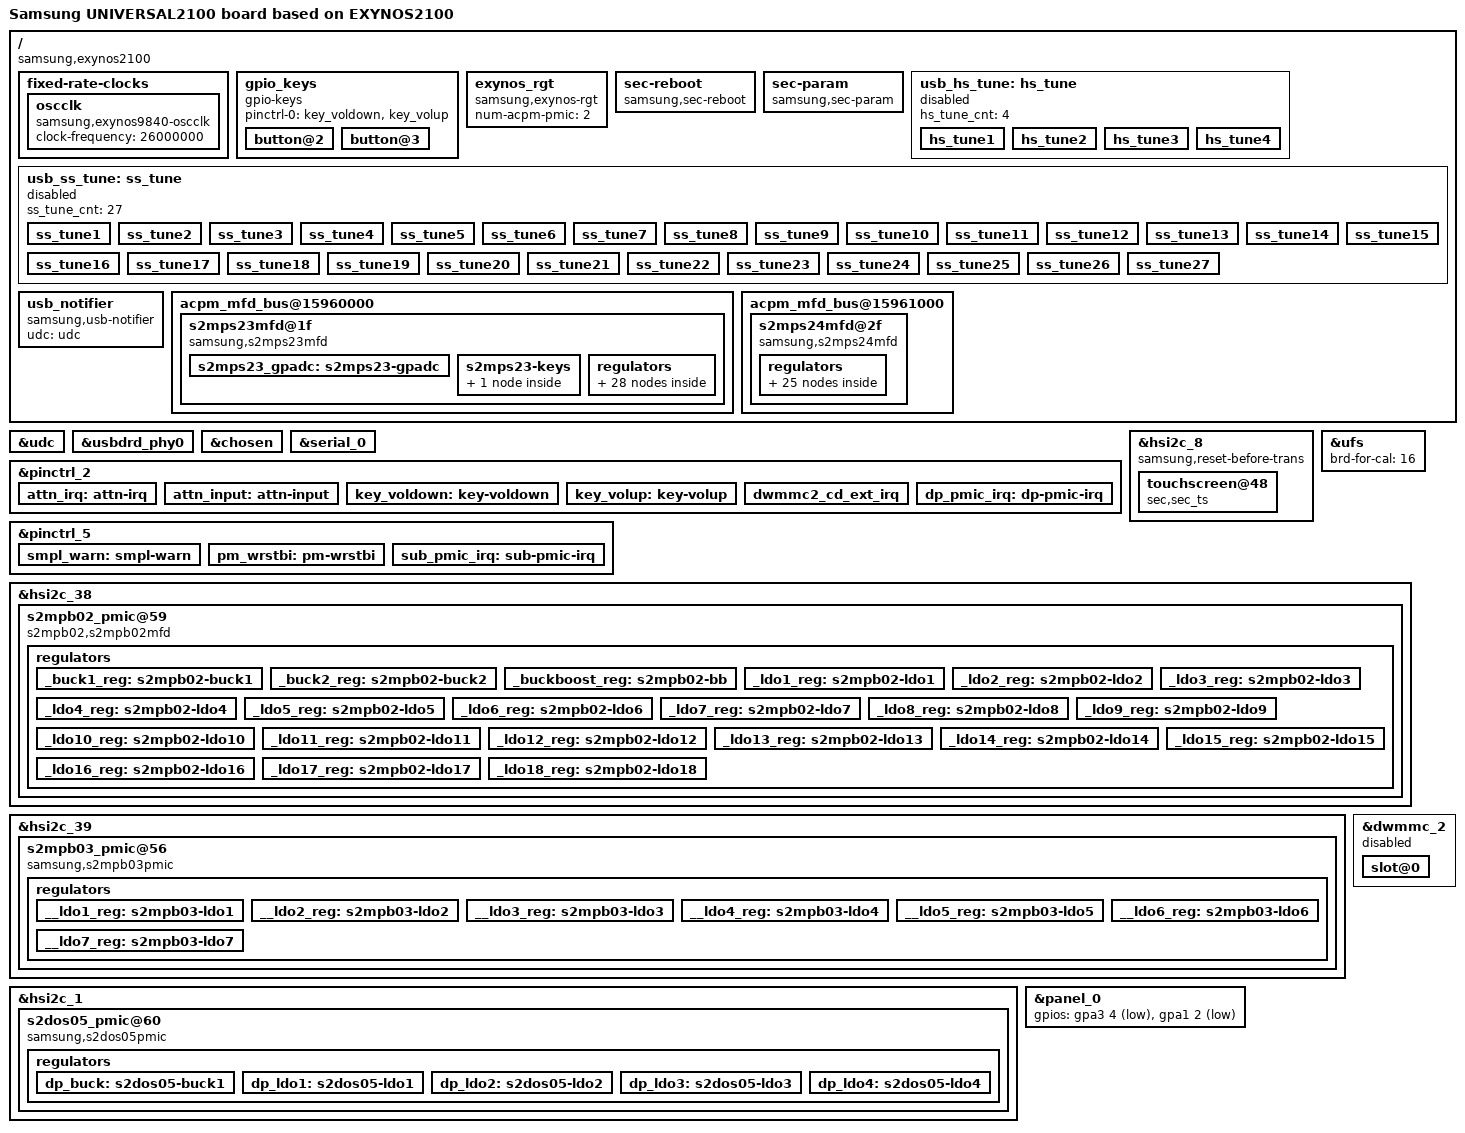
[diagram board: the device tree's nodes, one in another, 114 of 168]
/*
 * SAMSUNG EXYNOS2100 board device tree source
 *
 * Copyright (c) 2020 Samsung Electronics Co., Ltd.
 *		http://www.samsung.com
 *
 * This program is free software; you can redistribute it and/or modify
 * it under the terms of the GNU General Public License version 2 as
 * published by the Free Software Foundation.
*/

/dts-v1/;
/plugin/;
#include <dt-bindings/interrupt-controller/exynos2100.h>
#include <dt-bindings/clock/exynos9840.h>
#include <dt-bindings/display/exynos-display.h>
//#include <dt-bindings/pci/pci.h>
//#include "battery_data_universal2100_max77705.dtsi"
#include "exynos2100-universal2100_if-pmic-max77705.dtsi"
//#include "exynos2100-universal2100-cp-s5123ap-sipc.dtsi"

#define BOARD_ID	0x1
#define BOARD_REV	0x0

/ {
	compatible = "samsung,exynos2100", "samsung,UNIVERSAL2100";
	board_id = <BOARD_ID>;
	board_rev = <BOARD_REV>;

	fragment@model {
		target-path = "/";
		__overlay__ {
			#address-cells = <2>;
			#size-cells = <1>;

			model = "Samsung UNIVERSAL2100 board based on EXYNOS2100";

			fixed-rate-clocks {
				oscclk {
					compatible = "samsung,exynos9840-oscclk";
					clock-frequency = <26000000>;
				};
			};

			gpio_keys {
				status = "okay";
				compatible = "gpio-keys";
				pinctrl-names = "default";
				pinctrl-0 = <&key_voldown &key_volup>;

				button@2 {
					label = "gpio-keys: KEY_VOLUMEDOWN";
					linux,code = <114>;
					gpios = <&gpa0 4 0xf>;
				};
				button@3 {
					label = "gpio-keys: KEY_VOLUMEUP";
					linux,code = <115>;
					gpios = <&gpa0 3 0xf>;
				};
			};

			exynos_rgt {
				compatible = "samsung,exynos-rgt";
				num-acpm-pmic = <2>;
			};

			sec-reboot {
				compatible = "samsung,sec-reboot";
				samsung,syscon-phandle = <&pmu_system_controller>;
				reboot-offset = <0x3C00>; /* SYSTEM_CONFIGURATION */
				magic-inform = <0x0808>; /* INFORM2 */
				panic-inform = <0x080C>; /* INFORM3 */
			};

			sec-param {
				compatible = "samsung,sec-param";
				char-table-size = <3>;
				/* 2 columns for character type of param; offset size  */
				char-offset-table = <
					7340592 4    /* CM_OFFSET */
					7340644 4    /* PD_OFFSET */
					7340628 1 >; /* FMM_LOCK_OFFSET */
				u32-table-size = <1>;
				/* 1 column for u32 type of param; offset */
				u32-offset-table = <
					7340632 >;   /* WC_OFFSET */
			};

			usb_hs_tune:hs_tune {
				status = "disabled";
				hs_tune_cnt = <4>;
				/* value = <device host> */
				hs_tune1 {
					tune_name = "tx_pre_emp";
					tune_value = <0x3 0x3>;
				};

				hs_tune2 {
					tune_name = "tx_vref";
					tune_value = <0xc 0xc>;
				};

				hs_tune3 {
					tune_name = "rx_sqrx";
					tune_value = <0x5 0x5>;
				};

				hs_tune4 {
					tune_name = "utmi_clk";
					tune_value = <0x1 0x1>;
				};
			};

			usb_ss_tune:ss_tune {
				status = "disabled";
				ss_tune_cnt = <27>;
				/* value = <device host> */
				ss_tune1 {
					tune_name = "ssrx_sqhs_th_ssp";
					tune_value = <0x4 0x4>;
				};

				ss_tune2 {
					tune_name = "ssrx_lfps_th";
					tune_value = <0x2 0x2>;
				};

				ss_tune3 {
					tune_name = "ssrx_adap_coef_sel";
					tune_value = <0x1 0x1>;
				};

				ss_tune4 {
					tune_name = "ssrx_mf_eq_ctrl_ss";
					tune_value = <0x6 0x6>;
				};

				ss_tune5 {
					tune_name = "ssrx_mf_eq_ctrl_ssp";
					tune_value = <0x6 0x6>;
				};

				ss_tune6 {
					tune_name = "ssrx_hf_eq_ctrl_ss";
					tune_value = <0xe 0xe>;
				};

				ss_tune7 {
					tune_name = "ssrx_hf_eq_ctrl_ssp";
					tune_value = <0xe 0xe>;
				};

				ss_tune8 {
					tune_name = "ssrx_dfe_1tap_ctrl_ss";
					tune_value = <0x2 0x2>;
				};

				ss_tune9 {
					tune_name = "ssrx_dfe_1tap_ctrl_ssp";
					tune_value = <0x2 0x2>;
				};

				ss_tune10 {
					tune_name = "ssrx_dfe_2tap_ctrl_ss";
					tune_value = <0x0 0x0>;
				};

				ss_tune11 {
					tune_name = "ssrx_dfe_2tap_ctrl_ssp";
					tune_value = <0x0 0x0>;
				};

				ss_tune12 {
					tune_name = "ssrx_dfe_3tap_ctrl_ss";
					tune_value = <0x0 0x0>;
				};

				ss_tune13 {
					tune_name = "ssrx_dfe_3tap_ctrl_ssp";
					tune_value = <0x0 0x0>;
				};

				ss_tune14 {
					tune_name = "ssrx_dfe_4tap_ctrl_ss";
					tune_value = <0x0 0x0>;
				};

				ss_tune15 {
					tune_name = "ssrx_dfe_4tap_ctrl_ssp";
					tune_value = <0x0 0x0>;
				};

				ss_tune16 {
					tune_name = "ssrx_term_cal";
					tune_value = <0xb 0xb>;
				};

				ss_tune17 {
					tune_name = "sstx_amp_ss";
					tune_value = <0xb 0xb>;
				};

				ss_tune18 {
					tune_name = "sstx_deemp_ss";
					tune_value = <0x5 0x5>;
				};

				ss_tune19 {
					tune_name = "sstx_pre_shoot_ss";
					tune_value = <0x3 0x3>;
				};

				ss_tune20 {
					tune_name = "sstx_amp_ssp";
					tune_value = <0xb 0xb>;
				};

				ss_tune21 {
					tune_name = "sstx_deemp_ssp";
					tune_value = <0x5 0x5>;
				};

				ss_tune22 {
					tune_name = "sstx_pre_shoot_ssp";
					tune_value = <0x3 0x3>;
				};

				ss_tune23 {
					tune_name = "sstx_idrv_up";
					tune_value = <0x7 0x7>;
				};

				ss_tune24 {
					tune_name = "sstx_lfps_idrv_up";
					tune_value = <0x0 0x0>;
				};

				ss_tune25 {
					tune_name = "sstx_up_term";
					tune_value = <0x3 0x3>;
				};

				ss_tune26 {
					tune_name = "sstx_dn_term";
					tune_value = <0x3 0x3>;
				};

				ss_tune27 {
					tune_name = "rext_ovrd";
					tune_value = <0x0 0x0>; /* Use default */
				};
			};

			usb_notifier {
				compatible = "samsung,usb-notifier";
				udc = <&udc>;
				status = "okay";
			};

			acpm_mfd_bus@15960000 {
				status = "okay";
				#address-cells = <1>;
				#size-cells = <0>;
				s2mps23mfd@1f {
					compatible = "samsung,s2mps23mfd";
					acpm-ipc-channel = <2>;
					i2c-speedy-address;
					s2mps23,wakeup = "enabled";
					reg = <0x1f>;
					interrupts = <GIC_SPI INTREQ__COMB_NONSECURE_SYSREG_VGPIO2AP IRQ_TYPE_LEVEL_HIGH>;
					interrupt-parent = <&gic>;
					pinctrl-names = "default";
					pinctrl-0 = <&pm_wrstbi &smpl_warn>;
					gpios = <&gpg0 5 0>;
					/* RTC: wtsr/smpl */
					wtsr_en = "enabled"; /* enable */
					smpl_en = "enabled"; /* enable */
					wtsr_timer_val = <3>;	/* 1000ms */
					smpl_timer_val = <4>;	/* 500ms */
					sub_smpl_en = "enabled"; /* enable */
					check_jigon = <0>; /* do not check jigon */
					/* RTC: If it's first boot, reset rtc to 1/1/2020 12:00:00(Wed) */
					init_time,sec = <0>;
					init_time,min = <0>;
					init_time,hour = <12>;
					init_time,mday = <1>;
					init_time,mon = <0>;
					init_time,year = <120>;
					init_time,wday = <3>;
					/* SMPL_WARN */
					smpl_warn_en = <1>; /* 1 : enable , 0 : disable */
					/* range of SMPL_WARN_LEVEL */
					/* 0x00 : 2.1V, 0x20 : 2.3V, 0x40 : 2.5V, 0x60 : 2.7V 0x80 : 2.9V */
					/* 0xA0 : 3.1V, 0xC0 : 3.3V */
					smpl_warn_vth = <0xA0>;
					/* SMPL_WARN_HYS[4:3] 00(Reserved), 01(200mV), 10(300mV), 11(Reserved) */
					smpl_warn_hys = <0x08>;
					/* OCP_WARN */
					ocp_warn1_en = <0>; /* 1 : enable, 0 : disable */
					ocp_warn1_cnt = <0>; /* ocp warn reset timing control, 0 : 2 clock, 1 : 32 clock */
					ocp_warn1_dvs_mask = <0>; /* ocp warn mask when dvs, 0 : not masked, 1 : masked  */
					ocp_warn1_lv = <0x0>; /* step : -83mA */

					/* Power-meter */
					adc_mode = <1>; /* 0 : disable, 1 : power meter */

					/* CONTROL_SEL# */
					control_sel = <0x64 0x06 0x07 0x77 0x77 0x07 0x70 0x64 0x00 0x00
							0x70 0x88 0x98 0x99 0x09 0x0F 0x00 0x00 0x00 0x00
							0x00>;

					s2mps23_gpadc: s2mps23-gpadc {
						#io-channel-cells = <1>;
						io-channel-ranges;
						acpm-ipc-channel = <14>;
					};

					s2mps23-keys {
						button@1 {
							label = "pmic-keys: KEY_POWER";
							linux,code = <116>;
							wakeup = <1>;
						};
					};

					regulators {
						b1_reg: BUCK1 {
							regulator-name = "vdd_g3d";
							regulator-min-microvolt = <450000>;
							regulator-max-microvolt = <1300000>;
							regulator-always-on;
							regulator-ramp-delay = <6000>;
							regulator-initial-mode = <3>;
						};
/*
						b2_reg: BUCK2 {
							regulator-name = "vdd_lcpu_cp";
							regulator-min-microvolt = <450000>;
							regulator-max-microvolt = <1300000>;
							regulator-always-on;
							regulator-ramp-delay = <6000>;
							regulator-initial-mode = <3>;
						};

						b3_reg: BUCK3 {
							regulator-name = "vdd_cp";
							regulator-min-microvolt = <450000>;
							regulator-max-microvolt = <1300000>;
							regulator-always-on;
							regulator-ramp-delay = <6000>;
							regulator-initial-mode = <3>;
						};
*/
						b4_reg: BUCK4 {
							regulator-name = "vdd_int";
							regulator-min-microvolt = <450000>;
							regulator-max-microvolt = <1300000>;
							regulator-always-on;
							regulator-ramp-delay = <6000>;
							regulator-initial-mode = <3>;
						};

						b5_reg: BUCK5 {
							regulator-name = "vdd2h_mem";
							regulator-min-microvolt = <450000>;
							regulator-max-microvolt = <1300000>;
							regulator-always-on;
							regulator-ramp-delay = <6000>;
							regulator-initial-mode = <3>;
						};

						b6_reg: BUCK6 {
							regulator-name = "vddq_mem";
							regulator-min-microvolt = <400000>;
							regulator-max-microvolt = <1300000>;
							regulator-always-on;
							regulator-ramp-delay = <6000>;
							regulator-initial-mode = <3>;
						};

						b7_reg: BUCK7 {
							regulator-name = "vdd_lldo1";
							regulator-min-microvolt = <450000>;
							regulator-max-microvolt = <1300000>;
							regulator-always-on;
							regulator-ramp-delay = <6000>;
							regulator-initial-mode = <3>;
						};

						b8_reg: BUCK8 {
							regulator-name = "vdd_lldo2";
							regulator-min-microvolt = <900000>;
							regulator-max-microvolt = <1300000>;
							regulator-always-on;
							regulator-ramp-delay = <6000>;
							regulator-initial-mode = <3>;
						};

						b9_reg: BUCK9 {
							regulator-name = "vdd_mldo";
							regulator-min-microvolt = <1750000>;
							regulator-max-microvolt = <2150000>;
							regulator-always-on;
							regulator-ramp-delay = <6000>;
							regulator-initial-mode = <3>;
						};

						l1_reg: LDO1 {
							regulator-name = "vdd_ldo1";
							regulator-min-microvolt = <725000>;
							regulator-max-microvolt = <1300000>;
							regulator-always-on;
							regulator-ramp-delay = <12000>;
							regulator-initial-mode = <3>;
						};

						l2_reg: LDO2 {
							regulator-name = "vdd_ldo2";
							regulator-min-microvolt = <1600000>;
							regulator-max-microvolt = <1950000>;
							regulator-always-on;
							regulator-ramp-delay = <12000>;
							regulator-initial-mode = <3>;
						};
/*
						l3_reg: LDO3 {
							regulator-name = "vdd_ldo3";
							regulator-min-microvolt = <500000>;
							regulator-max-microvolt = <1187500>;
							regulator-always-on;
							regulator-ramp-delay = <12000>;
							regulator-initial-mode = <3>;
						};

						l4_reg: LDO4 {
							regulator-name = "vdd_ldo4";
							regulator-min-microvolt = <500000>;
							regulator-max-microvolt = <1300000>;
							regulator-always-on;
							regulator-ramp-delay = <12000>;
							regulator-initial-mode = <3>;
						};

						l5_reg: LDO5 {
							regulator-name = "vdd_ldo5";
							regulator-min-microvolt = <500000>;
							regulator-max-microvolt = <1300000>;
							regulator-always-on;
							regulator-ramp-delay = <12000>;
							regulator-initial-mode = <3>;
						};
*/
						l6_reg: LDO6 {
							regulator-name = "vdd_ldo6";
							regulator-min-microvolt = <500000>;
							regulator-max-microvolt = <1300000>;
							regulator-always-on;
							regulator-ramp-delay = <12000>;
							regulator-initial-mode = <3>;
						};
/*
						l7_reg: LDO7 {
							regulator-name = "vdd_ldo7";
							regulator-min-microvolt = <500000>;
							regulator-max-microvolt = <1300000>;
							regulator-always-on;
							regulator-ramp-delay = <6000>;
							regulator-initial-mode = <3>;
						};
*/
						l8_reg: LDO8 {
							regulator-name = "vdd_ldo8";
							regulator-min-microvolt = <725000>;
							regulator-max-microvolt = <1300000>;
							regulator-always-on;
							regulator-ramp-delay = <12000>;
							regulator-initial-mode = <3>;
						};

						l9_reg: LDO9 {
							regulator-name = "vdd_ldo9";
							regulator-min-microvolt = <725000>;
							regulator-max-microvolt = <1300000>;
							regulator-always-on;
							regulator-ramp-delay = <12000>;
							regulator-initial-mode = <3>;
						};

						l10_reg: LDO10 {
							regulator-name = "vdd085_usb";
							regulator-min-microvolt = <725000>;
							regulator-max-microvolt = <1300000>;
							regulator-always-on;
							regulator-ramp-delay = <12000>;
							regulator-initial-mode = <3>;
						};

						l11_reg: LDO11 {
							regulator-name = "vdd_ldo11";
							regulator-min-microvolt = <1600000>;
							regulator-max-microvolt = <1950000>;
							regulator-always-on;
							regulator-ramp-delay = <12000>;
							regulator-initial-mode = <3>;
						};

						l12_reg: LDO12 {
							regulator-name = "vdd18_usb";
							regulator-min-microvolt = <1600000>;
							regulator-max-microvolt = <1950000>;
							regulator-always-on;
							regulator-ramp-delay = <12000>;
							regulator-initial-mode = <3>;
						};

						l13_reg: LDO13 {
							regulator-name = "vdd_ldo13";
							regulator-min-microvolt = <725000>;
							regulator-max-microvolt = <1300000>;
							regulator-always-on;
							regulator-ramp-delay = <12000>;
							regulator-initial-mode = <3>;
						};
/*
						l14_reg: LDO14 {
							regulator-name = "vdd_ldo14";
							regulator-min-microvolt = <1600000>;
							regulator-max-microvolt = <1950000>;
							regulator-always-on;
							regulator-ramp-delay = <12000>;
							regulator-initial-mode = <3>;
						};

						l15_reg: LDO15 {
							regulator-name = "vdd_ldo15";
							regulator-min-microvolt = <1600000>;
							regulator-max-microvolt = <1950000>;
							regulator-always-on;
							regulator-ramp-delay = <12000>;
							regulator-initial-mode = <3>;
						};

						l16_reg: LDO16 {
							regulator-name = "vdd_ldo16";
							regulator-min-microvolt = <1600000>;
							regulator-max-microvolt = <1950000>;
							regulator-always-on;
							regulator-ramp-delay = <12000>;
							regulator-initial-mode = <3>;
						};

						l17_reg: LDO17 {
							regulator-name = "vdd_ldo17";
							regulator-min-microvolt = <725000>;
							regulator-max-microvolt = <1300000>;
							regulator-always-on;
							regulator-ramp-delay = <12000>;
							regulator-initial-mode = <3>;
						};

						l18_reg: LDO18 {
							regulator-name = "vdd_ldo18";
							regulator-min-microvolt = <500000>;
							regulator-max-microvolt = <1300000>;
							regulator-always-on;
							regulator-ramp-delay = <12000>;
							regulator-initial-mode = <3>;
						};
*/
						l19_reg: LDO19 {
							regulator-name = "vdd_ldo19";
							regulator-min-microvolt = <1600000>;
							regulator-max-microvolt = <1950000>;
							regulator-always-on;
							regulator-ramp-delay = <12000>;
							regulator-initial-mode = <3>;
						};
/*
						l20_reg: LDO20 {
							regulator-name = "vdd_ldo20";
							regulator-min-microvolt = <1600000>;
							regulator-max-microvolt = <1950000>;
							regulator-always-on;
							regulator-ramp-delay = <12000>;
							regulator-initial-mode = <3>;
						};

						l21_reg: LDO21 {
							regulator-name = "vdd_ldo21";
							regulator-min-microvolt = <1600000>;
							regulator-max-microvolt = <1950000>;
							regulator-always-on;
							regulator-ramp-delay = <12000>;
							regulator-initial-mode = <3>;
						};
*/
						l22_reg: LDO22 {
							regulator-name = "vdd_ldo22";
							regulator-min-microvolt = <1600000>;
							regulator-max-microvolt = <1950000>;
							regulator-always-on;
							regulator-ramp-delay = <12000>;
							regulator-initial-mode = <3>;
						};

						l23_reg: LDO23 {
							regulator-name = "vdd_ldo23";
							regulator-min-microvolt = <1600000>;
							regulator-max-microvolt = <1950000>;
							regulator-always-on;
							regulator-ramp-delay = <12000>;
							regulator-initial-mode = <3>;
						};

						l24_reg: LDO24 {
							regulator-name = "vdd_ldo24";
							regulator-min-microvolt = <1600000>;
							regulator-max-microvolt = <1950000>;
							regulator-always-on;
							regulator-ramp-delay = <12000>;
							regulator-initial-mode = <3>;
						};

						l25_reg: LDO25 {
							regulator-name = "vdd_ldo25";
							regulator-min-microvolt = <725000>;
							regulator-max-microvolt = <1300000>;
							regulator-always-on;
							regulator-ramp-delay = <12000>;
							regulator-initial-mode = <3>;
						};

						l26_reg: LDO26 {
							regulator-name = "vdd_ldo26";
							regulator-min-microvolt = <1600000>;
							regulator-max-microvolt = <1950000>;
							regulator-always-on;
							regulator-ramp-delay = <12000>;
							regulator-initial-mode = <3>;
						};

						l27_reg: LDO27 {
							regulator-name = "vdd_ldo27";
							regulator-min-microvolt = <1600000>;
							regulator-max-microvolt = <1950000>;
							regulator-always-on;
							regulator-ramp-delay = <12000>;
							regulator-initial-mode = <3>;
						};

						l28_reg: LDO28 {
							regulator-name = "vdd_ldo28";
							regulator-min-microvolt = <1600000>;
							regulator-max-microvolt = <1950000>;
							regulator-always-on;
							regulator-ramp-delay = <12000>;
							regulator-initial-mode = <3>;
						};

						l29_reg: LDO29 {
							regulator-name = "vdd_ldo29";
							regulator-min-microvolt = <1600000>;
							regulator-max-microvolt = <1950000>;
							regulator-always-on;
							regulator-ramp-delay = <12000>;
							regulator-initial-mode = <3>;
						};

						l30_reg: LDO30 {
							regulator-name = "vdd_ldo30";
							regulator-min-microvolt = <1600000>;
							regulator-max-microvolt = <1950000>;
							regulator-always-on;
							regulator-ramp-delay = <12000>;
							regulator-initial-mode = <3>;
						};

						l31_reg: LDO31 {
							regulator-name = "vdd_ldo31";
							regulator-min-microvolt = <1600000>;
							regulator-max-microvolt = <1950000>;
							regulator-always-on;
							regulator-ramp-delay = <12000>;
							regulator-initial-mode = <3>;
						};

						l32_reg: LDO32 {
							regulator-name = "vdd_ldo32";
							regulator-min-microvolt = <1600000>;
							regulator-max-microvolt = <1950000>;
							regulator-always-on;
							regulator-ramp-delay = <12000>;
							regulator-initial-mode = <3>;
						};
					}; /* end of regulators */
				}; /* end of s2mps23mfd@00 */
			}; /* end of acpm_mfd_bus@11a10000 */

			acpm_mfd_bus@15961000 {
				status = "okay";
				#address-cells = <1>;
				#size-cells = <0>;

				s2mps24mfd@2f {
					compatible = "samsung,s2mps24mfd";
					acpm-ipc-channel = <2>;
					i2c-speedy-address;
					s2mps24,wakeup = "enabled";
					reg = <0x2f>;
					wtsr_en = <1>; /* 0 : disable, 1: enable */
					/* OCP_WARN */
					ocp_warn2_en = <0>; /* 1 : enable, 0 : disable */
					ocp_warn2_cnt = <0>; /* ocp warn reset timing control, 0 : 2 clock, 1 : 32 clock */
					ocp_warn2_dvs_mask = <0>; /* ocp warn mask when dvs, 0 : not masked, 1 : masked  */
					ocp_warn2_lv = <0x0>; /* step : -250mA */
					ocp_warn3_en = <0>; /* 1 : enable, 0 : disable */
					ocp_warn3_cnt = <0>; /* ocp warn reset timing control, 0 : 2 clock, 1 : 32 clock */
					ocp_warn3_dvs_mask = <0>; /* ocp warn mask when dvs, 0 : not masked, 1 : masked  */
					ocp_warn3_lv = <0x0>; /* step : -250mA */
					ocp_warn4_en = <0>; /* 1 : enable, 0 : disable */
					ocp_warn4_cnt = <0>; /* ocp warn reset timing control, 0 : 2 clock, 1 : 32 clock */
					ocp_warn4_dvs_mask = <0>; /* ocp warn mask when dvs, 0 : not masked, 1 : masked  */
					ocp_warn4_lv = <0x0>; /* step : -250mA */

					/* Power-meter */
					adc_mode = <1>; /* 0 : disable, 1 : power meter */

					/* CONTROL_SEL# */
					control_sel = <0x10 0xDC 0x50 0x7E 0x17 0xC5 0x00 0x60 0x06 0x88
							0x98 0x99 0x00 0x00 0x00 0x0D>;
					regulators {
						s_b1_reg: BUCK1 {
							regulator-name = "vdd_cam";
							regulator-min-microvolt = <450000>;
							regulator-max-microvolt = <1300000>;
							regulator-always-on;
							regulator-ramp-delay = <6000>;
							regulator-initial-mode = <3>;
						};

						s_b2_reg: BUCK2 {
							regulator-name = "vdd_cpucl0_lit";
							regulator-min-microvolt = <450000>;
							regulator-max-microvolt = <1300000>;
							regulator-always-on;
							regulator-ramp-delay = <6000>;
							regulator-initial-mode = <3>;
						};

						s_b3_reg: BUCK3 {
							regulator-name = "vdd_cpucl1_mid";
							regulator-min-microvolt = <450000>;
							regulator-max-microvolt = <1300000>;
							regulator-always-on;
							regulator-ramp-delay = <6000>;
							regulator-initial-mode = <3>;
						};

						s_b4_reg: BUCK4 {
							regulator-name = "vdd_cpucl2_big";
							regulator-min-microvolt = <450000>;
							regulator-max-microvolt = <1300000>;
							regulator-always-on;
							regulator-ramp-delay = <6000>;
							regulator-initial-mode = <3>;
						};

						s_b5_reg: BUCK5 {
							regulator-name = "vdd_mif";
							regulator-min-microvolt = <450000>;
							regulator-max-microvolt = <1300000>;
							regulator-always-on;
							regulator-ramp-delay = <6000>;
							regulator-initial-mode = <3>;
						};

						s_b6_reg: BUCK6 {
							regulator-name = "vdd_npu";
							regulator-min-microvolt = <450000>;
							regulator-max-microvolt = <1300000>;
							regulator-always-on;
							regulator-ramp-delay = <6000>;
							regulator-initial-mode = <3>;
						};

						s_b7_reg: BUCK7 {
							regulator-name = "vdd_lldo1s";
							regulator-min-microvolt = <900000>;
							regulator-max-microvolt = <1400000>;
							regulator-always-on;
							regulator-ramp-delay = <6000>;
							regulator-initial-mode = <3>;
						};

						s_b8_reg: BUCK8 {
							regulator-name = "vdd_lldo2s";
							regulator-min-microvolt = <900000>;
							regulator-max-microvolt = <1400000>;
							regulator-always-on;
							regulator-ramp-delay = <6000>;
							regulator-initial-mode = <3>;
						};

						s_bb_reg: BUCKB {
							regulator-name = "vdd_hldo";
							regulator-min-microvolt = <3000000>;
							regulator-max-microvolt = <3600000>;
							regulator-always-on;
							regulator-ramp-delay = <6000>;
							regulator-initial-mode = <3>;
						};

						s_l1_reg: LDO1 {
							regulator-name = "vdd_ldo1s";
							regulator-min-microvolt = <500000>;
							regulator-max-microvolt = <1300000>;
							regulator-always-on;
							regulator-ramp-delay = <12000>;
							regulator-initial-mode = <3>;
						};

						s_l2_reg: LDO2 {
							regulator-name = "vdd_ldo2s";
							regulator-min-microvolt = <500000>;
							regulator-max-microvolt = <1300000>;
							regulator-always-on;
							regulator-ramp-delay = <12000>;
							regulator-initial-mode = <3>;
						};

						s_l3_reg: LDO3 {
							regulator-name = "vdd_ldo3s";
							regulator-min-microvolt = <500000>;
							regulator-max-microvolt = <1300000>;
							regulator-always-on;
							regulator-ramp-delay = <12000>;
							regulator-initial-mode = <3>;
						};

						s_l4_reg: LDO4 {
							regulator-name = "vdd_ldo4s";
							regulator-min-microvolt = <725000>;
							regulator-max-microvolt = <1300000>;
							regulator-always-on;
							regulator-ramp-delay = <12000>;
							regulator-initial-mode = <3>;
						};
/*
						s_l5_reg: LDO5 {
							regulator-name = "vdd_ldo5s";
							regulator-min-microvolt = <725000>;
							regulator-max-microvolt = <1300000>;
							regulator-always-on;
							regulator-ramp-delay = <12000>;
							regulator-initial-mode = <3>;
						};
*/
						s_l6_reg: LDO6 {
							regulator-name = "vdd33_usb";
							regulator-min-microvolt = <1800000>;
							regulator-max-microvolt = <3375000>;
							regulator-always-on;
							regulator-ramp-delay = <12000>;
							regulator-initial-mode = <3>;
						};

						s_l7_reg: LDO7 {
							regulator-name = "vdd_ldo7s";
							regulator-min-microvolt = <1800000>;
							regulator-max-microvolt = <3375000>;
							regulator-always-on;
							regulator-ramp-delay = <12000>;
							regulator-initial-mode = <3>;
						};

						s_l8_reg: LDO8 {
							regulator-name = "vdd_ldo8s";
							regulator-min-microvolt = <1800000>;
							regulator-max-microvolt = <3375000>;
							regulator-always-on;
							regulator-ramp-delay = <12000>;
							regulator-initial-mode = <3>;
						};

						s_l9_reg: LDO9 {
							regulator-name = "vqmmc";
							regulator-min-microvolt = <1800000>;
							regulator-max-microvolt = <3375000>;
							regulator-always-on;
							regulator-ramp-delay = <12000>;
							regulator-initial-mode = <3>;
						};
/*
						s_l10_reg: LDO10 {
							regulator-name = "vdd_ldo10s";
							regulator-min-microvolt = <725000>;
							regulator-max-microvolt = <1300000>;
							regulator-always-on;
							regulator-ramp-delay = <12000>;
							regulator-initial-mode = <3>;
						};

						s_l11_reg: LDO11 {
							regulator-name = "vdd_ldo11s";
							regulator-min-microvolt = <725000>;
							regulator-max-microvolt = <1300000>;
							regulator-always-on;
							regulator-ramp-delay = <12000>;
							regulator-initial-mode = <3>;
						};

						s_l12_reg: LDO12 {
							regulator-name = "vdd_ldo12s";
							regulator-min-microvolt = <1800000>;
							regulator-max-microvolt = <3375000>;
							regulator-always-on;
							regulator-ramp-delay = <12000>;
							regulator-initial-mode = <3>;
						};

						s_l13_reg: LDO13 {
							regulator-name = "vdd_ldo13s";
							regulator-min-microvolt = <725000>;
							regulator-max-microvolt = <1300000>;
							regulator-always-on;
							regulator-ramp-delay = <12000>;
							regulator-initial-mode = <3>;
						};
*/
						s_l14_reg: LDO14 {
							regulator-name = "vdd_ldo14s";
							regulator-min-microvolt = <725000>;
							regulator-max-microvolt = <1300000>;
							regulator-always-on;
							regulator-ramp-delay = <12000>;
							regulator-initial-mode = <3>;
						};
/*
						s_l15_reg: LDO15 {
							regulator-name = "vdd_ldo15s";
							regulator-min-microvolt = <725000>;
							regulator-max-microvolt = <1300000>;
							regulator-always-on;
							regulator-ramp-delay = <12000>;
							regulator-initial-mode = <3>;
						};
*/
						s_l16_reg: LDO16 {
							regulator-name = "vdd_ldo16s";
							regulator-min-microvolt = <725000>;
							regulator-max-microvolt = <1300000>;
							regulator-always-on;
							regulator-ramp-delay = <12000>;
							regulator-initial-mode = <3>;
						};

						s_l17_reg: LDO17 {
							regulator-name = "vmmc";
							regulator-min-microvolt = <1800000>;
							regulator-max-microvolt = <3375000>;
							regulator-always-on;
							regulator-ramp-delay = <12000>;
							regulator-initial-mode = <3>;
						};

						s_l18_reg: LDO18 {
							regulator-name = "vdd_ldo18s";
							regulator-min-microvolt = <1800000>;
							regulator-max-microvolt = <3375000>;
							regulator-always-on;
							regulator-ramp-delay = <12000>;
							regulator-initial-mode = <3>;
						};

						s_l19_reg: LDO19 {
							regulator-name = "vdd_ldo19s";
							regulator-min-microvolt = <1800000>;
							regulator-max-microvolt = <3375000>;
							regulator-always-on;
							regulator-ramp-delay = <12000>;
							regulator-initial-mode = <3>;
						};

						s_l20_reg: LDO20 {
							regulator-name = "vdd_ldo20s";
							regulator-min-microvolt = <1800000>;
							regulator-max-microvolt = <3375000>;
							regulator-always-on;
							regulator-ramp-delay = <12000>;
							regulator-initial-mode = <3>;
						};

						s_l21_reg: LDO21 {
							regulator-name = "vdd_ldo21s";
							regulator-min-microvolt = <1800000>;
							regulator-max-microvolt = <3375000>;
							regulator-always-on;
							regulator-ramp-delay = <12000>;
							regulator-initial-mode = <3>;
						};

						s_l22_reg: LDO22 {
							regulator-name = "vdd_ldo22s";
							regulator-min-microvolt = <500000>;
							regulator-max-microvolt = <1300000>;
							regulator-always-on;
							regulator-ramp-delay = <12000>;
							regulator-initial-mode = <3>;
						};
					}; /* end of regulators */
				}; /* end of s2mps24mfd@00 */
			}; /* end of acpm_mfd_bus@11061000 */
		}; /* end of __overlay__ */
	}; /* end of fragment */
}; /* end of root */

&udc {
	status = "okay";
	dr_mode = "otg";
	maximum-speed = "high-speed";
	snps,quirk-frame-length-adjustment = <0x20>;
	snps,u1u2_exitfail_quirk;
	/* ux_exit_in_px should be defined in MK, LT */
	snps,ux_exit_in_px_quirk;
	/* elastic_buf_mode_quirk should be defined in MK */
	snps,elastic_buf_mode_quirk;
	/* usb3-lpm-capable; */
	/* snps,usb3_lpm_capable; */
	/*
	 * dis-u2-freeclk-exists-quirk, dis_u2_susphy_quirk are alternative.
	 * One of them should be selected
	 */
	snps,dis-u2-freeclk-exists-quirk;
	/*snps,dis_u2_susphy_quirk;*/

	usb_audio_offloading = <0>;
	/* abox = <&abox>;  Temporary block */
	/* check susphy support */
	xhci_l2_support = <0>;
};

&usbdrd_phy0 {
	status = "okay";
	use_default_tune_val = <0x1>;

	pinctrl-names = "default";
	/* pinctrl-0 = <&phy_port>; */
	/* phy,gpio_phy_port = <&gpg0 4 0x0>; */
	hs_tune_param = <&usb_hs_tune>;
	ss_tune_param = <&usb_ss_tune>;
};

&chosen {
	bootargs_ext = "earlycon=exynos4210,0x10540000 console=ttySAC0,115200n8 androidboot.boot_devices=13100000.ufs";
};

&serial_0 {
	status = "okay";
};

&pinctrl_2 {
	attn_irq: attn-irq {
		samsung,pins = "gpa1-0";
		samsung,pin-function = <0xf>;
		samsung,pin-pud = <3>;
		samsung,pin-drv = <3>;
	};

	attn_input: attn-input {
		samsung,pins = "gpa1-0";
		samsung,pin-function = <0>;
		samsung,pin-pud = <1>;
	};

	key_voldown: key-voldown {
		samsung,pins = "gpa0-4";
		samsung,pin-function = <0xf>;
		samsung,pin-pud = <3>;
		samsung,pin-drv = <3>;
	};

	key_volup: key-volup {
		samsung,pins = "gpa0-3";
		samsung,pin-function = <0xf>;
		samsung,pin-pud = <3>;
		samsung,pin-drv = <3>;
	};

	dwmmc2_cd_ext_irq: dwmmc2_cd_ext_irq {
		samsung,pins = "gpa1-5";
		samsung,pin-function = <0xf>;
		samsung,pin-pud = <3>;
		samsung,pin-drv = <4>;
	};
};

&hsi2c_8 {
	#address-cells = <1>;
	#size-cells = <0>;
	status = "okay";
	samsung,reset-before-trans;
	touchscreen@48 {
		compatible = "sec,sec_ts";
		reg = <0x48>;
		pinctrl-names = "on_state", "off_state";
		pinctrl-0 = <&attn_irq>;
		pinctrl-1 = <&attn_input>;
		pressure-sensor = "Y";
		sec,irq_gpio = <&gpa1 0 0>;
		sec,irq_type = <8200>;
		sec,max_coords = <4095 4095>;
		sec,mis_cal_check = <1>;
		sec,regulator_dvdd = "S2MPB02_LDO6";
		sec,regulator_avdd = "S2MPB02_LDO18";
		sec,regulator_boot_on;
		sec,always_lpmode = <1>;
		sec,project_name = "olympus";
	};
};

/*
&pcie_0 {
	status = "okay";
	use-sysmmu = "false";
	use-cache-coherency = "false";
	use-msi = "false";
	ep-device-type = <EP_BCM_WIFI>;
	pcie,wlan-gpio = <&gpp12 2 0x1>;
};

&pcie_1 {
	status = "disabled";
	use-sysmmu = "false";
	use-cache-coherency = "true";
	use-msi = "true";
	use-sicd = "false";
	phy-power-off = "false";
	ep-device-type = <EP_SAMSUNG_MODEM>;
};
*/

&ufs {
	/* board type for UFS CAL */
	brd-for-cal = /bits/ 8 <16>;  /* (1:SMDK, 16:UNIV) board */
};

&pinctrl_2 {
	dp_pmic_irq: dp-pmic-irq {
		samsung,pins = "gpa1-4";
		samsung,pin-function = <0>;
		samsung,pin-pud = <0>;
		samsung,pin-drv = <0>;
	};
};

&pinctrl_5 {
	smpl_warn: smpl-warn {
		   samsung,pins = "gpg0-5";
		   samsung,pin-function = <15>;
		   samsung,pin-pud = <0>;
		   samsung,pin-drv = <0>;
	};

	pm_wrstbi: pm-wrstbi {
		   samsung,pins = "gpp14-1";
		   samsung,pin-con-pdn = <3>;
	};

	sub_pmic_irq: sub-pmic-irq {
		samsung,pins = "gpp14-2";
		samsung,pin-function = <0>;
		samsung,pin-pud = <0>;
		samsung,pin-drv = <0>;
	};
};

&hsi2c_38 {
	#address-cells = <1>;
	#size-cells = <0>;
	status = "okay";
	s2mpb02_pmic@59 {
		compatible = "s2mpb02,s2mpb02mfd";
		reg = <0x59>;

		s2mpb02,wakeup;
		pinctrl-names = "default";
		pinctrl-0 = <&sub_pmic_irq>;

		regulators {
			_buck1_reg: s2mpb02-buck1 {
				    regulator-name = "S2MPB02_BUCK1";
				    regulator-min-microvolt = <600000>;
				    regulator-max-microvolt = <1700000>;
				    regulator-always-on;
				    regulator-boot-on;
			};

			_buck2_reg: s2mpb02-buck2 {
				    regulator-name = "S2MPB02_BUCK2";
				    regulator-min-microvolt = <1050000>;
				    regulator-max-microvolt = <1050000>;
			};

			_buckboost_reg: s2mpb02-bb {
					regulator-name = "S2MPB02_BB";
					regulator-min-microvolt = <2600000>;
					regulator-max-microvolt = <4000000>;
					regulator-always-on;
					regulator-boot-on;
			};

			_ldo1_reg: s2mpb02-ldo1 {
				   regulator-name = "S2MPB02_LDO1";
				   regulator-min-microvolt = <900000>;
				   regulator-max-microvolt = <900000>;
				   regulator-always-on;
			};

			_ldo2_reg: s2mpb02-ldo2 {
				   regulator-name = "S2MPB02_LDO2";
				   regulator-min-microvolt = <1000000>;
				   regulator-max-microvolt = <1000000>;
			};

			_ldo3_reg: s2mpb02-ldo3 {
				   regulator-name = "S2MPB02_LDO3";
				   regulator-min-microvolt = <1200000>;
				   regulator-max-microvolt = <1200000>;
			};

			_ldo4_reg: s2mpb02-ldo4 {
				   regulator-name = "S2MPB02_LDO4";
				   regulator-min-microvolt = <1200000>;
				   regulator-max-microvolt = <1200000>;
			};

			_ldo5_reg: s2mpb02-ldo5 {
				   regulator-name = "S2MPB02_LDO5";
				   regulator-min-microvolt = <1200000>;
				   regulator-max-microvolt = <1200000>;
			};

			_ldo6_reg: s2mpb02-ldo6 {
				   regulator-name = "S2MPB02_LDO6";
				   regulator-min-microvolt = <1800000>;
				   regulator-max-microvolt = <1800000>;
				   regulator-always-on;
				   regulator-boot-on;
			};

			_ldo7_reg: s2mpb02-ldo7 {
				   regulator-name = "S2MPB02_LDO7";
				   regulator-min-microvolt = <1800000>;
				   regulator-max-microvolt = <1800000>;
			};

			_ldo8_reg: s2mpb02-ldo8 {
				   regulator-name = "S2MPB02_LDO8";
				   regulator-min-microvolt = <1800000>;
				   regulator-max-microvolt = <1800000>;
			};

			_ldo9_reg: s2mpb02-ldo9 {
				   regulator-name = "S2MPB02_LDO9";
				   regulator-min-microvolt = <1800000>;
				   regulator-max-microvolt = <1800000>;
				   regulator-always-on;
				   regulator-boot-on;
			};

			_ldo10_reg: s2mpb02-ldo10 {
				    regulator-name = "S2MPB02_LDO10";
				    regulator-min-microvolt = <1800000>;
				    regulator-max-microvolt = <1800000>;
			};

			_ldo11_reg: s2mpb02-ldo11 {
				    regulator-name = "S2MPB02_LDO11";
				    regulator-min-microvolt = <2800000>;
				    regulator-max-microvolt = <2800000>;
				    regulator-always-on;
				    regulator-boot-on;
			};

			_ldo12_reg: s2mpb02-ldo12 {
				    regulator-name = "S2MPB02_LDO12";
				    regulator-min-microvolt = <2800000>;
				    regulator-max-microvolt = <2800000>;
			};

			_ldo13_reg: s2mpb02-ldo13 {
				    regulator-name = "S2MPB02_LDO13";
				    regulator-min-microvolt = <2900000>;
				    regulator-max-microvolt = <2900000>;
			};

			_ldo14_reg: s2mpb02-ldo14 {
				    regulator-name = "S2MPB02_LDO14";
				    regulator-min-microvolt = <2800000>;
				    regulator-max-microvolt = <2800000>;
			};

			_ldo15_reg: s2mpb02-ldo15 {
				    regulator-name = "S2MPB02_LDO15";
				    regulator-min-microvolt = <2800000>;
				    regulator-max-microvolt = <2800000>;
			};

			_ldo16_reg: s2mpb02-ldo16 {
				    regulator-name = "S2MPB02_LDO16";
				    regulator-min-microvolt = <2800000>;
				    regulator-max-microvolt = <2800000>;
			};

			_ldo17_reg: s2mpb02-ldo17 {
				    regulator-name = "S2MPB02_LDO17";
				    regulator-min-microvolt = <2950000>;
				    regulator-max-microvolt = <2950000>;
			};

			_ldo18_reg: s2mpb02-ldo18 {
				    regulator-name = "S2MPB02_LDO18";
				    regulator-min-microvolt = <3300000>;
				    regulator-max-microvolt = <3300000>;
				    regulator-always-on;
				    regulator-boot-on;
			};
		};
	};
};

&hsi2c_39 {
	#address-cells = <1>;
	#size-cells = <0>;
	status = "okay";
	s2mpb03_pmic@56 {
		compatible = "samsung,s2mpb03pmic";
		reg = <0x56>;

		s2mpb03,wakeup;

		regulators {
			__ldo1_reg: s2mpb03-ldo1 {
				regulator-name = "VDDD_1.05V_SUB";
				regulator-min-microvolt = <1050000>;
				regulator-max-microvolt = <1050000>;
			};

			__ldo2_reg: s2mpb03-ldo2 {
				regulator-name = "VDDD_1.05V_CAM";
				regulator-min-microvolt = <1050000>;
				regulator-max-microvolt = <1050000>;
			};

			__ldo3_reg: s2mpb03-ldo3 {
				regulator-name = "VDDIO_1.8V_CAM";
				regulator-min-microvolt = <1800000>;
				regulator-max-microvolt = <1800000>;
			};

			__ldo4_reg: s2mpb03-ldo4 {
				regulator-name = "VDDD_RET_1.0V_CAM";
				regulator-min-microvolt = <700000>;
				regulator-max-microvolt = <1025000>;
			};

			__ldo5_reg: s2mpb03-ldo5 {
				regulator-name = "VDDA_2.8V_CAM";
				regulator-min-microvolt = <2800000>;
				regulator-max-microvolt = <2800000>;
			};

			__ldo6_reg: s2mpb03-ldo6 {
				regulator-name = "VDDA_2.8V_SUB";
				regulator-min-microvolt = <2800000>;
				regulator-max-microvolt = <2800000>;
			};

			__ldo7_reg: s2mpb03-ldo7 {
				regulator-name = "VDD_VM_2.8V_OIS";
				regulator-min-microvolt = <2800000>;
				regulator-max-microvolt = <2800000>;
			};
		};
	};
};

&hsi2c_1 {
	#address-cells = <1>;
	#size-cells = <0>;
	status = "okay";
	s2dos05_pmic@60 {
		compatible = "samsung,s2dos05pmic";
		reg = <0x60>;
		s2dos05,wakeup;
		pinctrl-names = "default";
		pinctrl-0 = <&dp_pmic_irq>;
		s2dos05,s2dos05_int = <&gpa1 4 0>;
		adc_mode = <1>; /* 0 : disable, 1 : current meter, 2 : power meter */
		adc_sync_mode = <2>; /* 1 : sync mode, 2 : async mode */
		regulators {
			dp_buck: s2dos05-buck1 {
				regulator-name = "vdd1";
				regulator-min-microvolt = <850000>;
				regulator-max-microvolt = <2100000>;
				regulator-always-on;
				regulator-boot-on;
			};
			dp_ldo1: s2dos05-ldo1 {
				regulator-name = "vdd2";
				regulator-min-microvolt = <1500000>;
				regulator-max-microvolt = <2000000>;
				regulator-always-on;
				regulator-boot-on;
			};
			dp_ldo2: s2dos05-ldo2 {
				regulator-name = "vdd3";
				regulator-min-microvolt = <1500000>;
				regulator-max-microvolt = <2000000>;
				regulator-always-on;
				regulator-boot-on;
			};
			dp_ldo3: s2dos05-ldo3{
				regulator-name = "vdd4";
				regulator-min-microvolt = <2700000>;
				regulator-max-microvolt = <3775000>;
				regulator-always-on;
				regulator-boot-on;
			};
			dp_ldo4: s2dos05-ldo4{
				regulator-name = "vdd5";
				regulator-min-microvolt = <2700000>;
				regulator-max-microvolt = <3775000>;
				regulator-always-on;
				regulator-boot-on;
			};
		};
	};
};

&panel_0 {
	/* reset, power */
	gpios = <&gpa3 4 0x1>, <&gpa1 2 0x1>;
};

&dwmmc_2 {
	#address-cells = <1>;
	#size-cells = <0>;
	status = "disabled";
	num-slots = <1>;
	supports-4bit;
	supports-cmd23;
	supports-erase;
	supports-highspeed;
	sd-uhs-sdr50;
	sd-uhs-sdr104;
	card-detect-gpio;
	bypass-for-allpass;
	use-fine-tuning;
	card-init-hwacg-ctrl;
	skip-init-mmc-scan;
	fifo-depth = <0x40>;
	qos_dvfs_level = <400000>;
	desc-size = <4>;
	card-detect-delay = <200>;
	data-timeout = <200>;
	hto-timeout = <80>;
	samsung,dw-mshc-ciu-div = <3>;
	clock-frequency = <800000000>;
	samsung,dw-mshc-sdr-timing = <3 0 2 0>;
	samsung,dw-mshc-ddr-timing = <3 0 2 1>;
	samsung,dw-mshc-sdr50-timing = <3 0 4 2>;
	samsung,dw-mshc-sdr104-timing = <3 0 3 0>;

	num-ref-clks = <9>;
	ciu_clkin = <25 50 50 25 50 100 200 50 50>;

	/* Swapping clock drive strength */
	clk-drive-number = <6>;
	pinctrl-names = "default",
		"fast-slew-rate-1x",
		"fast-slew-rate-1_5x",
		"fast-slew-rate-2x",
		"fast-slew-rate-2_5x",
		"fast-slew-rate-3x",
		"fast-slew-rate-4x",
		"pins-as-pdn",
		"pins-as-func";
	pinctrl-0 = <&sd2_clk &sd2_cmd &sd2_bus1 &sd2_bus4 &dwmmc2_cd_ext_irq>;
	pinctrl-1 = <&sd2_clk_fast_slew_rate_1x>;
	pinctrl-2 = <&sd2_clk_fast_slew_rate_1_5x>;
	pinctrl-3 = <&sd2_clk_fast_slew_rate_2x>;
	pinctrl-4 = <&sd2_clk_fast_slew_rate_2_5x>;
	pinctrl-5 = <&sd2_clk_fast_slew_rate_3x>;
	pinctrl-6 = <&sd2_clk_fast_slew_rate_4x>;
	pinctrl-7 = <&sd2_pins_as_pdn>;
	pinctrl-8 = <&sd2_clk &sd2_cmd &sd2_bus1 &sd2_bus4>;

	card-detect = <&gpa1 5 0xf>;
	slot@0 {
		reg = <0>;
		bus-width = <4>;
		disable-wp;
	};
};
